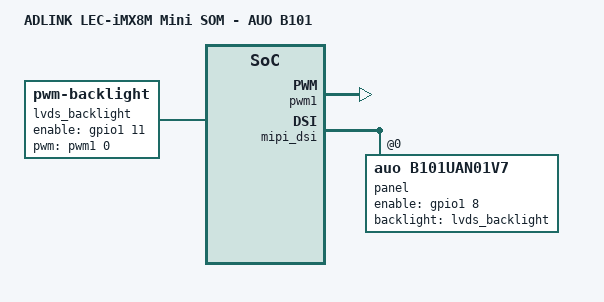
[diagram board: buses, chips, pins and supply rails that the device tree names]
/*
 *
 */


#include "lec-imx8mm.dts"

/{
	model = "ADLINK LEC-iMX8M Mini SOM - AUO B101";
	
	lvds_backlight: lvds_backlight {
		compatible = "pwm-backlight";
		pwms = <&pwm1 0 100000>;
		enable-gpios = <&gpio1 11 GPIO_ACTIVE_HIGH>;		
		brightness-levels = < 0  1  2  3  4  5  6  7  8  9
				     10 11 12 13 14 15 16 17 18 19
				     20 21 22 23 24 25 26 27 28 29
				     30 31 32 33 34 35 36 37 38 39
				     40 41 42 43 44 45 46 47 48 49
				     50 51 52 53 54 55 56 57 58 59
				     60 61 62 63 64 65 66 67 68 69
				     70 71 72 73 74 75 76 77 78 79
				     80 81 82 83 84 85 86 87 88 89
				     90 91 92 93 94 95 96 97 98 99
				    100>;
		default-brightness-level = <80>;
		status = "okay";
	};
};

&pwm1 {
	pinctrl-names = "default";
	pinctrl-0 = <&pinctrl_mipi_dsi_pwm>;
	status = "okay";
};

&iomuxc {
	pinctrl_mipi_dsi_blkt_en: mipi_dsi_blkt_engrp {    
		fsl,pins = <
		    MX8MM_IOMUXC_GPIO1_IO11_GPIO1_IO11	19
		>;
	};

	pinctrl_mipi_dsi_pwm: mipi_dsi_pwmgrp {            
		fsl,pins = <
		    MX8MM_IOMUXC_GPIO1_IO01_PWM1_OUT	0x116
		>;
	};
};

&mipi_dsi {
	status = "okay";
	panel@0 {
		compatible = "auo,b101uan01v7";
		reg = <0>;
		pinctrl-0 = <&pinctrl_mipi_dsi_blkt_en>;
		enable-gpios = <&gpio1 8 GPIO_ACTIVE_HIGH>;
		status = "okay";
		dsi-lanes = <4>;
		video-mode = <0>;
		panel-width-mm = <293>;
		panel-height-mm = <165>;
		backlight = <&lvds_backlight>;
		display-timings {
			timing {
				clock-frequency = <148000000>;
				hactive = <1920>;
				vactive = <1200>;
				hfront-porch = <77>;
				hsync-len = <56>;
				hback-porch = <117>;
				vfront-porch = <11>;
				vsync-len = <19>;
				vback-porch = <19>;
				hsync-active = <0>;
				vsync-active = <0>;
				de-active = <0>;
				pixelclk-active = <0>;
			};
		};
	};
};

